# BL808 register map
File version: 0.1
Registers are access not given, no defined reset value unless marked. A register's access mark holds for its fields unless they carry their own. Offsets are from the block's base; [hi:lo] are bit positions; {n}, {i} and the like mark numbered series.

## GLB
Base 0x20000000
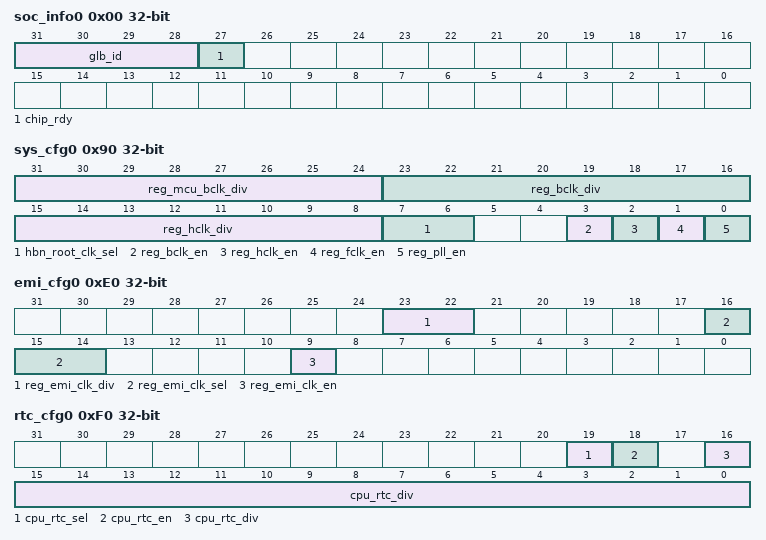
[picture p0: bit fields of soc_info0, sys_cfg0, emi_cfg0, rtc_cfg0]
0x00 soc_info0
  [31:28] glb_id ro, [27] chip_rdy ro
0x50 core_cfg16 ro
  [31:0] np_int_sta0
0x54 core_cfg17 ro
  [31:0] np_int_sta1
0x58 core_cfg18 rw
  [31:0] np_int_mask0
0x5C core_cfg19 rw
  [31:0] np_int_mask1
0x60 core_cfg20 write-once
  [31:0] np_int_clr0
0x64 core_cfg21 write-once
  [31:0] np_int_clr1
0x90 sys_cfg0
  [31:24] reg_mcu_bclk_div rw, [23:16] reg_bclk_div rw, [15:8] reg_hclk_div rw, [7:6] hbn_root_clk_sel ro, [3] reg_bclk_en rw, [2] reg_hclk_en rw, [1] reg_fclk_en rw, [0] reg_pll_en rw
0x94 sys_cfg1
  [26:24] fclk_sw_state ro
0xA0 bus_cfg0
  [15:0] rg_apb2_pck_force rw
0xE0 emi_cfg0
  [23:22] reg_emi_clk_div rw, [16:14] reg_emi_clk_sel rw, [9] reg_emi_clk_en rw
0xF0 rtc_cfg0
  [19] cpu_rtc_sel rw, [18] cpu_rtc_en rw, [16:0] cpu_rtc_div rw
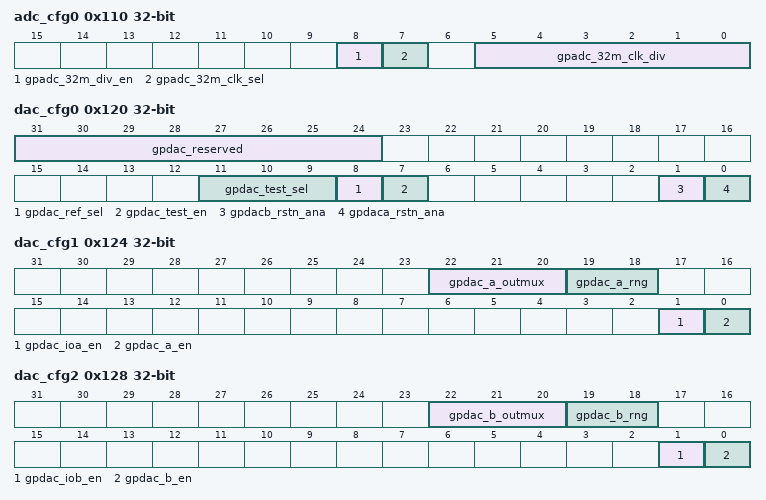
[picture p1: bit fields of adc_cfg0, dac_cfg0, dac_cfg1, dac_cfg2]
0x110 adc_cfg0
  [8] gpadc_32m_div_en rw, [7] gpadc_32m_clk_sel rw, [5:0] gpadc_32m_clk_div rw
0x120 dac_cfg0
  [31:24] gpdac_reserved rw, [11:9] gpdac_test_sel rw, [8] gpdac_ref_sel rw, [7] gpdac_test_en rw, [1] gpdacb_rstn_ana rw, [0] gpdaca_rstn_ana rw
0x124 dac_cfg1
  [22:20] gpdac_a_outmux rw, [19:18] gpdac_a_rng rw, [1] gpdac_ioa_en rw, [0] gpdac_a_en rw
0x128 dac_cfg2
  [22:20] gpdac_b_outmux rw, [19:18] gpdac_b_rng rw, [1] gpdac_iob_en rw, [0] gpdac_b_en rw
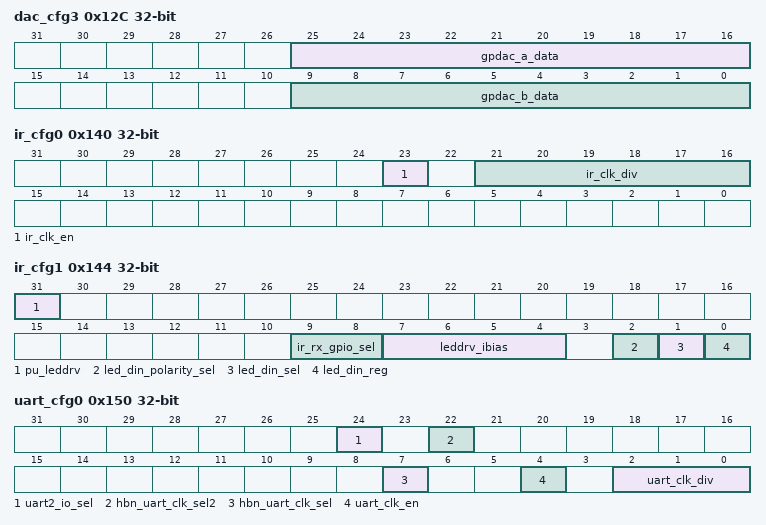
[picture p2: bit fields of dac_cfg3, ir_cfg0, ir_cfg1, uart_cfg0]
0x12C dac_cfg3
  [25:16] gpdac_a_data rw, [9:0] gpdac_b_data rw
0x130 dma_cfg0
  [31:24] dma_clk_en rw
0x134 dma_cfg1
  [31:24] dma2_clk_en rw
0x138 dma_cfg2 rw
  [31:0] reg_dma_cn_sel
0x140 ir_cfg0
  [23] ir_clk_en rw, [21:16] ir_clk_div rw
0x144 ir_cfg1
  [31] pu_leddrv rw, [9:8] ir_rx_gpio_sel rw, [7:4] leddrv_ibias rw, [2] led_din_polarity_sel rw, [1] led_din_sel rw, [0] led_din_reg rw
0x150 uart_cfg0
  [24] uart2_io_sel rw, [22] hbn_uart_clk_sel2 ro, [7] hbn_uart_clk_sel ro, [4] uart_clk_en rw, [2:0] uart_clk_div rw
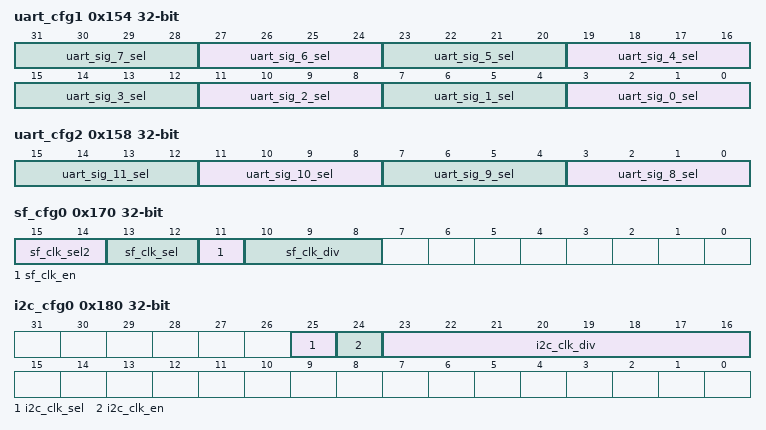
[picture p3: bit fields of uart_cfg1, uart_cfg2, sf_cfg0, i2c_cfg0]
0x154 uart_cfg1 rw
  [4n+3:4n] uart_sig_{n}_sel (n=0..7)
0x158 uart_cfg2
  [4n-29:4n-32] uart_sig_{n}_sel rw (n=8..11)
0x170 sf_cfg0
  [15:14] sf_clk_sel2 rw, [13:12] sf_clk_sel rw, [11] sf_clk_en rw, [10:8] sf_clk_div rw
0x180 i2c_cfg0
  [25] i2c_clk_sel rw, [24] i2c_clk_en rw, [23:16] i2c_clk_div rw
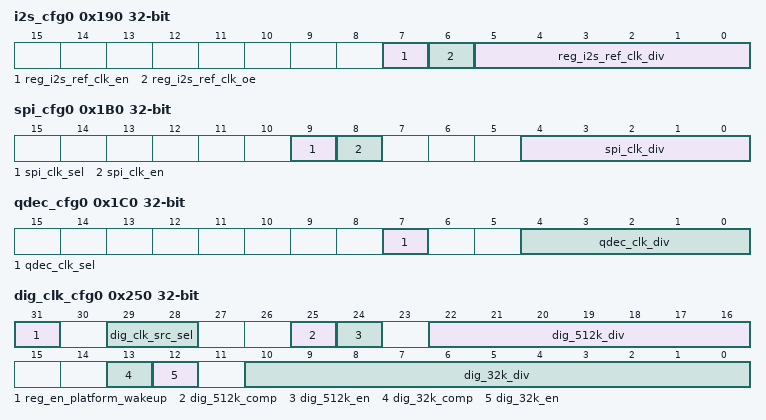
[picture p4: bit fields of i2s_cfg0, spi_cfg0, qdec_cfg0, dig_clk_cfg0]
0x190 i2s_cfg0
  [7] reg_i2s_ref_clk_en rw, [6] reg_i2s_ref_clk_oe rw, [5:0] reg_i2s_ref_clk_div rw
0x1B0 spi_cfg0
  [9] spi_clk_sel rw, [8] spi_clk_en rw, [4:0] spi_clk_div rw
0x1C0 qdec_cfg0
  [7] qdec_clk_sel rw, [4:0] qdec_clk_div rw
0x250 dig_clk_cfg0
  [31] reg_en_platform_wakeup rw, [29:28] dig_clk_src_sel rw, [25] dig_512k_comp rw, [24] dig_512k_en rw, [22:16] dig_512k_div rw, [13] dig_32k_comp rw, [12] dig_32k_en rw, [10:0] dig_32k_div rw
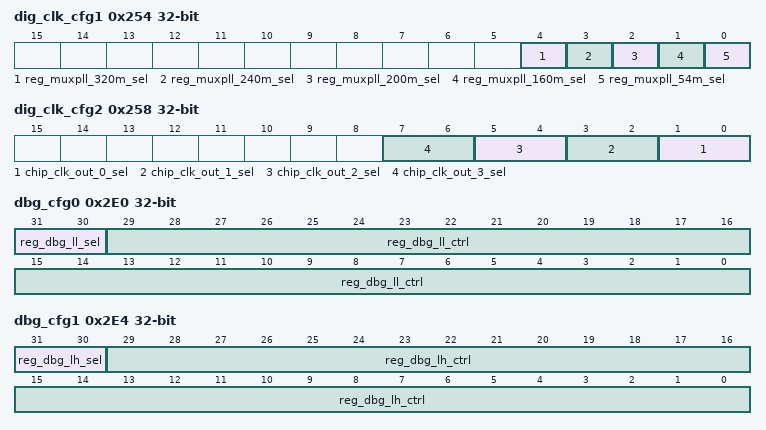
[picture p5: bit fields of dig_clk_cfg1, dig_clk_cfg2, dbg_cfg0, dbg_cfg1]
0x254 dig_clk_cfg1
  [4] reg_muxpll_320m_sel rw, [3] reg_muxpll_240m_sel rw, [2] reg_muxpll_200m_sel rw, [1] reg_muxpll_160m_sel rw, [0] reg_muxpll_54m_sel rw
0x258 dig_clk_cfg2
  [2n+1:2n] chip_clk_out_{n}_sel rw (n=0..3)
0x260 rf_cfg0
  [9] cfg_inv_rf2_test_clk_o rw
0x2E0 dbg_cfg0 rw
  [31:30] reg_dbg_ll_sel, [29:0] reg_dbg_ll_ctrl
0x2E4 dbg_cfg1 rw
  [31:30] reg_dbg_lh_sel, [29:0] reg_dbg_lh_ctrl
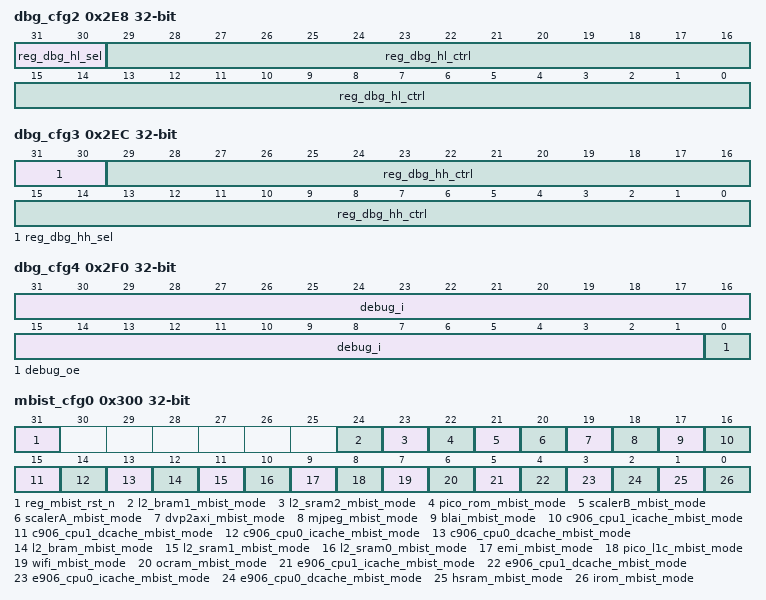
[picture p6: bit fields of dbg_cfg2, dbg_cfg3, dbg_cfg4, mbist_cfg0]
0x2E8 dbg_cfg2 rw
  [31:30] reg_dbg_hl_sel, [29:0] reg_dbg_hl_ctrl
0x2EC dbg_cfg3 rw
  [31:30] reg_dbg_hh_sel, [29:0] reg_dbg_hh_ctrl
0x2F0 dbg_cfg4 access per field
  [31:1] debug_i ro, [0] debug_oe rw
0x300 mbist_cfg0
  [31] reg_mbist_rst_n rw, [24] l2_bram1_mbist_mode rw, [23] l2_sram2_mbist_mode rw, [22] pico_rom_mbist_mode rw, [21] scalerB_mbist_mode rw, [20] scalerA_mbist_mode rw, [19] dvp2axi_mbist_mode rw, [18] mjpeg_mbist_mode rw, [17] blai_mbist_mode rw, [16] c906_cpu1_icache_mbist_mode rw, [15] c906_cpu1_dcache_mbist_mode rw, [14] c906_cpu0_icache_mbist_mode rw, [13] c906_cpu0_dcache_mbist_mode rw, [12] l2_bram_mbist_mode rw, [11] l2_sram1_mbist_mode rw, [10] l2_sram0_mbist_mode rw, [9] emi_mbist_mode rw, [8] pico_l1c_mbist_mode rw, [7] wifi_mbist_mode rw, [6] ocram_mbist_mode rw, [5] e906_cpu1_icache_mbist_mode rw, [4] e906_cpu1_dcache_mbist_mode rw, [3] e906_cpu0_icache_mbist_mode rw, [2] e906_cpu0_dcache_mbist_mode rw, [1] hsram_mbist_mode rw, [0] irom_mbist_mode rw
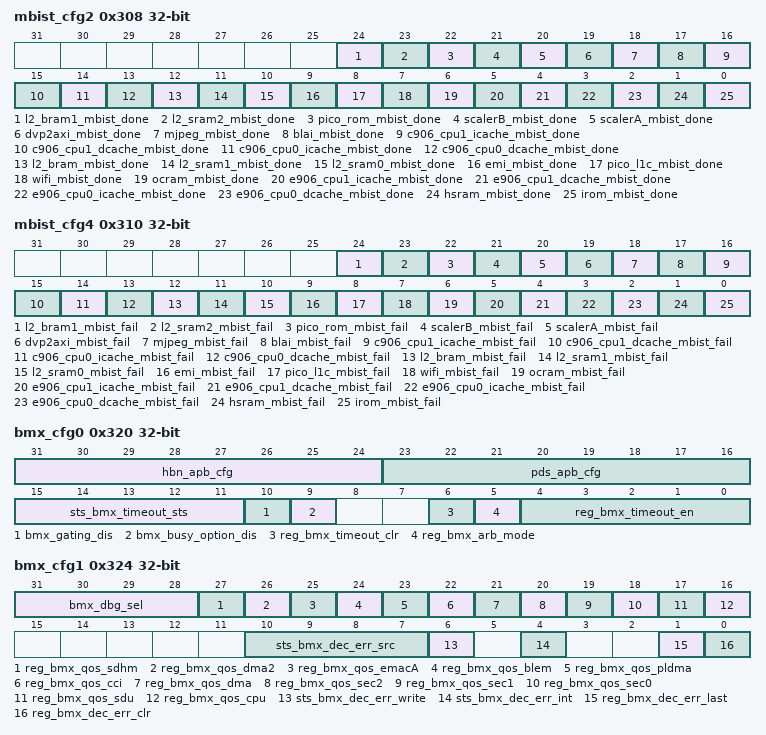
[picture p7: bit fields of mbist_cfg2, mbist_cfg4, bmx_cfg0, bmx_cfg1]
0x308 mbist_cfg2
  [24] l2_bram1_mbist_done ro, [23] l2_sram2_mbist_done ro, [22] pico_rom_mbist_done ro, [21] scalerB_mbist_done ro, [20] scalerA_mbist_done ro, [19] dvp2axi_mbist_done ro, [18] mjpeg_mbist_done ro, [17] blai_mbist_done ro, [16] c906_cpu1_icache_mbist_done ro, [15] c906_cpu1_dcache_mbist_done ro, [14] c906_cpu0_icache_mbist_done ro, [13] c906_cpu0_dcache_mbist_done ro, [12] l2_bram_mbist_done ro, [11] l2_sram1_mbist_done ro, [10] l2_sram0_mbist_done ro, [9] emi_mbist_done ro, [8] pico_l1c_mbist_done ro, [7] wifi_mbist_done ro, [6] ocram_mbist_done ro, [5] e906_cpu1_icache_mbist_done ro, [4] e906_cpu1_dcache_mbist_done ro, [3] e906_cpu0_icache_mbist_done ro, [2] e906_cpu0_dcache_mbist_done ro, [1] hsram_mbist_done ro, [0] irom_mbist_done ro
0x310 mbist_cfg4
  [24] l2_bram1_mbist_fail ro, [23] l2_sram2_mbist_fail ro, [22] pico_rom_mbist_fail ro, [21] scalerB_mbist_fail ro, [20] scalerA_mbist_fail ro, [19] dvp2axi_mbist_fail ro, [18] mjpeg_mbist_fail ro, [17] blai_mbist_fail ro, [16] c906_cpu1_icache_mbist_fail ro, [15] c906_cpu1_dcache_mbist_fail ro, [14] c906_cpu0_icache_mbist_fail ro, [13] c906_cpu0_dcache_mbist_fail ro, [12] l2_bram_mbist_fail ro, [11] l2_sram1_mbist_fail ro, [10] l2_sram0_mbist_fail ro, [9] emi_mbist_fail ro, [8] pico_l1c_mbist_fail ro, [7] wifi_mbist_fail ro, [6] ocram_mbist_fail ro, [5] e906_cpu1_icache_mbist_fail ro, [4] e906_cpu1_dcache_mbist_fail ro, [3] e906_cpu0_icache_mbist_fail ro, [2] e906_cpu0_dcache_mbist_fail ro, [1] hsram_mbist_fail ro, [0] irom_mbist_fail ro
0x320 bmx_cfg0
  [31:24] hbn_apb_cfg rw, [23:16] pds_apb_cfg rw, [15:11] sts_bmx_timeout_sts ro, [10] bmx_gating_dis rw, [9] bmx_busy_option_dis rw, [6] reg_bmx_timeout_clr rw, [5] reg_bmx_arb_mode rw, [4:0] reg_bmx_timeout_en rw
0x324 bmx_cfg1
  [31:28] bmx_dbg_sel rw, [27] reg_bmx_qos_sdhm rw, [26] reg_bmx_qos_dma2 rw, [25] reg_bmx_qos_emacA rw, [24] reg_bmx_qos_blem rw, [23] reg_bmx_qos_pldma rw, [22] reg_bmx_qos_cci rw, [21] reg_bmx_qos_dma rw, [20] reg_bmx_qos_sec2 rw, [19] reg_bmx_qos_sec1 rw, [18] reg_bmx_qos_sec0 rw, [17] reg_bmx_qos_sdu rw, [16] reg_bmx_qos_cpu rw, [10:7] sts_bmx_dec_err_src ro, [6] sts_bmx_dec_err_write ro, [4] sts_bmx_dec_err_int ro, [1] reg_bmx_dec_err_last rw, [0] reg_bmx_dec_err_clr rw
0x328 bmx_cfg2 ro
  [31:0] sts_bmx_dec_err_addr
0x32C bmx_cfg3 ro
  [31:0] bmx_dbg_out
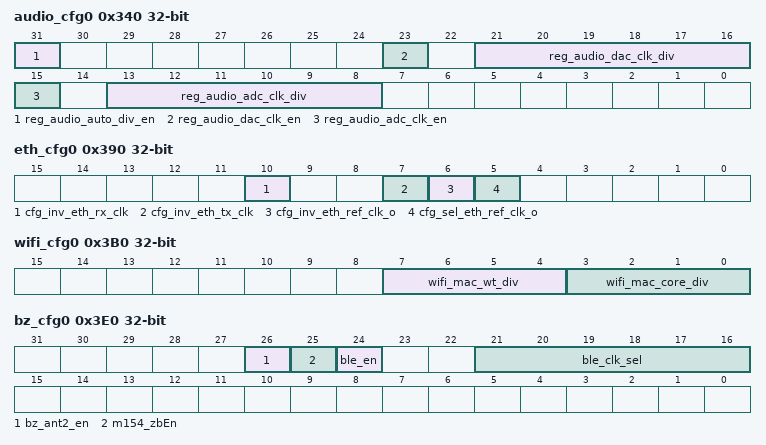
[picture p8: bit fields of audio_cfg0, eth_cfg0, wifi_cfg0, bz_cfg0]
0x340 audio_cfg0
  [31] reg_audio_auto_div_en rw, [23] reg_audio_dac_clk_en rw, [21:16] reg_audio_dac_clk_div rw, [15] reg_audio_adc_clk_en rw, [13:8] reg_audio_adc_clk_div rw
0x390 eth_cfg0
  [10] cfg_inv_eth_rx_clk rw, [7] cfg_inv_eth_tx_clk rw, [6] cfg_inv_eth_ref_clk_o rw, [5] cfg_sel_eth_ref_clk_o rw
0x3B0 wifi_cfg0
  [7:4] wifi_mac_wt_div rw, [3:0] wifi_mac_core_div rw
0x3D0 m154_cfg0
  [25] m1542_zbEn rw
0x3E0 bz_cfg0
  [26] bz_ant2_en rw, [25] m154_zbEn rw, [24] ble_en rw, [21:16] ble_clk_sel rw
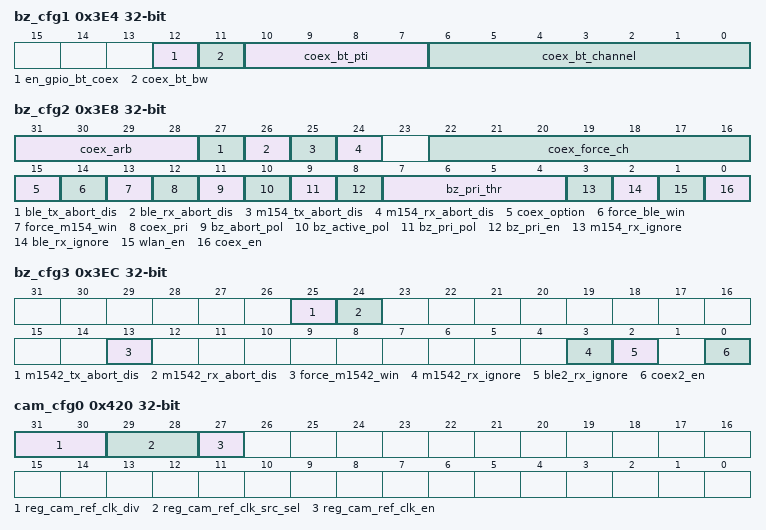
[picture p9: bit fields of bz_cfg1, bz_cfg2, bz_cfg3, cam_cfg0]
0x3E4 bz_cfg1
  [12] en_gpio_bt_coex rw, [11] coex_bt_bw rw, [10:7] coex_bt_pti rw, [6:0] coex_bt_channel rw
0x3E8 bz_cfg2
  [31:28] coex_arb ro, [27] ble_tx_abort_dis rw, [26] ble_rx_abort_dis rw, [25] m154_tx_abort_dis rw, [24] m154_rx_abort_dis rw, [22:16] coex_force_ch rw, [15] coex_option rw, [14] force_ble_win rw, [13] force_m154_win rw, [12] coex_pri rw, [11] bz_abort_pol rw, [10] bz_active_pol rw, [9] bz_pri_pol rw, [8] bz_pri_en rw, [7:4] bz_pri_thr rw, [3] m154_rx_ignore rw, [2] ble_rx_ignore rw, [1] wlan_en rw, [0] coex_en rw
0x3EC bz_cfg3
  [25] m1542_tx_abort_dis rw, [24] m1542_rx_abort_dis rw, [13] force_m1542_win rw, [3] m1542_rx_ignore rw, [2] ble2_rx_ignore rw, [0] coex2_en rw
0x420 cam_cfg0
  [31:30] reg_cam_ref_clk_div rw, [29:28] reg_cam_ref_clk_src_sel rw, [27] reg_cam_ref_clk_en rw
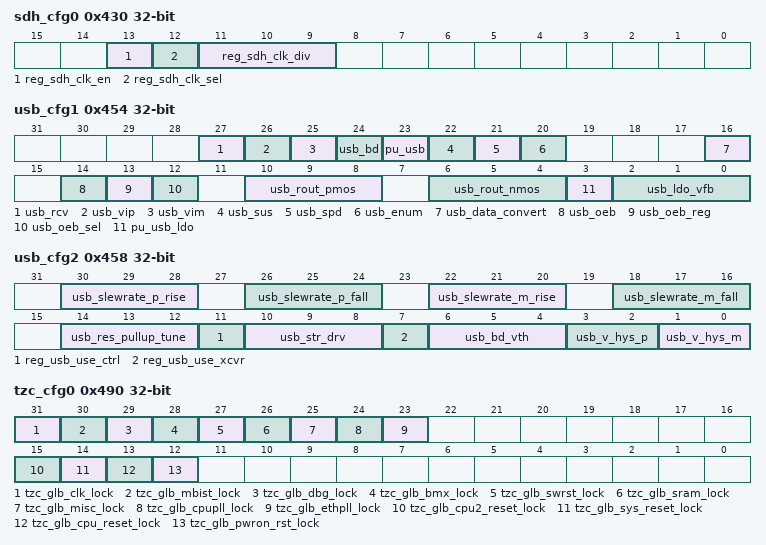
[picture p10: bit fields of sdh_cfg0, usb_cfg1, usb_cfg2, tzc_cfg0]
0x430 sdh_cfg0
  [13] reg_sdh_clk_en rw, [12] reg_sdh_clk_sel rw, [11:9] reg_sdh_clk_div rw
0x450 usb_cfg0
  [8] usb_clk_en rw
0x454 usb_cfg1
  [27] usb_rcv ro, [26] usb_vip ro, [25] usb_vim ro, [24] usb_bd ro, [23] pu_usb rw, [22] usb_sus rw, [21] usb_spd rw, [20] usb_enum rw, [16] usb_data_convert rw, [14] usb_oeb ro, [13] usb_oeb_reg rw, [12] usb_oeb_sel rw, [10:8] usb_rout_pmos rw, [6:4] usb_rout_nmos rw, [3] pu_usb_ldo rw, [2:0] usb_ldo_vfb rw
0x458 usb_cfg2
  [30:28] usb_slewrate_p_rise rw, [26:24] usb_slewrate_p_fall rw, [22:20] usb_slewrate_m_rise rw, [18:16] usb_slewrate_m_fall rw, [14:12] usb_res_pullup_tune rw, [11] reg_usb_use_ctrl rw, [10:8] usb_str_drv rw, [7] reg_usb_use_xcvr rw, [6:4] usb_bd_vth rw, [3:2] usb_v_hys_p rw, [1:0] usb_v_hys_m rw
0x490 tzc_cfg0
  [31] tzc_glb_clk_lock ro, [30] tzc_glb_mbist_lock ro, [29] tzc_glb_dbg_lock ro, [28] tzc_glb_bmx_lock ro, [27] tzc_glb_swrst_lock ro, [26] tzc_glb_sram_lock ro, [25] tzc_glb_misc_lock ro, [24] tzc_glb_cpupll_lock ro, [23] tzc_glb_ethpll_lock ro, [15] tzc_glb_cpu2_reset_lock ro, [14] tzc_glb_sys_reset_lock ro, [13] tzc_glb_cpu_reset_lock ro, [12] tzc_glb_pwron_rst_lock ro
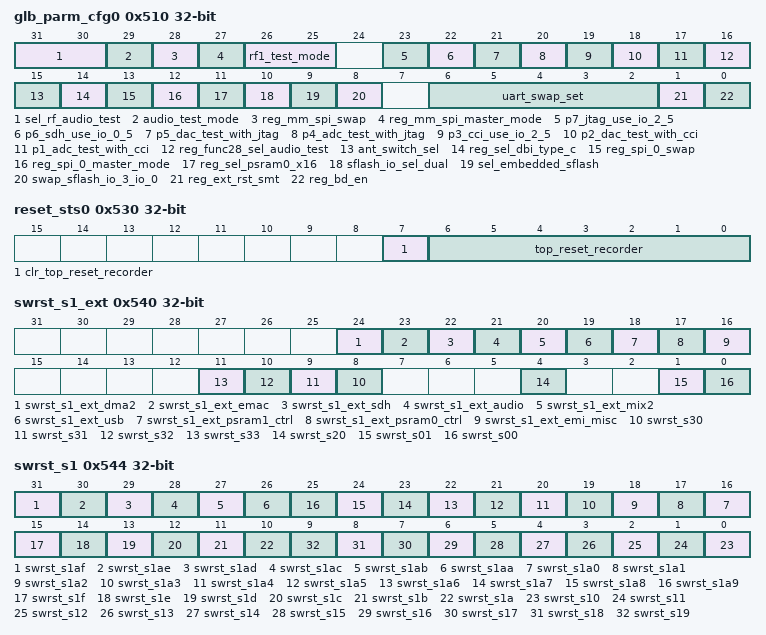
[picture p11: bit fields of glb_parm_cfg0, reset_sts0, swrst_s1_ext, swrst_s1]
0x510 glb_parm_cfg0
  [31:30] sel_rf_audio_test rw, [29] audio_test_mode rw, [28] reg_mm_spi_swap rw, [27] reg_mm_spi_master_mode rw, [26:25] rf1_test_mode rw, [23] p7_jtag_use_io_2_5 rw, [22] p6_sdh_use_io_0_5 rw, [21] p5_dac_test_with_jtag rw, [20] p4_adc_test_with_jtag rw, [19] p3_cci_use_io_2_5 rw, [18] p2_dac_test_with_cci rw, [17] p1_adc_test_with_cci rw, [16] reg_func28_sel_audio_test rw, [15] ant_switch_sel rw, [14] reg_sel_dbi_type_c rw, [13] reg_spi_0_swap rw, [12] reg_spi_0_master_mode rw, [11] reg_sel_psram0_x16 rw, [10] sflash_io_sel_dual rw, [9] sel_embedded_sflash rw, [8] swap_sflash_io_3_io_0 rw, [6:2] uart_swap_set rw, [1] reg_ext_rst_smt rw, [0] reg_bd_en rw
0x520 debug_cfg0
0x524 debug_cfg1
  [20] debug_ndreset_gate rw
0x530 reset_sts0
  [7] clr_top_reset_recorder rw, [6:0] top_reset_recorder ro
0x540 swrst_s1_ext + swrst_s3 + swrst_s2
  [24] swrst_s1_ext_dma2 rw, [23] swrst_s1_ext_emac rw, [22] swrst_s1_ext_sdh rw, [21] swrst_s1_ext_audio rw, [20] swrst_s1_ext_mix2 rw, [19] swrst_s1_ext_usb rw, [18] swrst_s1_ext_psram1_ctrl rw, [17] swrst_s1_ext_psram0_ctrl rw, [16] swrst_s1_ext_emi_misc rw, [n-22] swrst_s{n} rw (n=30..33), [4] swrst_s20 rw, [1] swrst_s01 rw, [0] swrst_s00 rw
0x544 swrst_s1 rw
  [31] swrst_s1af, [30] swrst_s1ae, [29] swrst_s1ad, [28] swrst_s1ac, [27] swrst_s1ab, [26] swrst_s1aa, [n+16] swrst_s1a{n} (n=0..9), [15] swrst_s1f, [14] swrst_s1e, [13] swrst_s1d, [12] swrst_s1c, [11] swrst_s1b, [10] swrst_s1a, [n-10] swrst_s{n} (n=10..19)
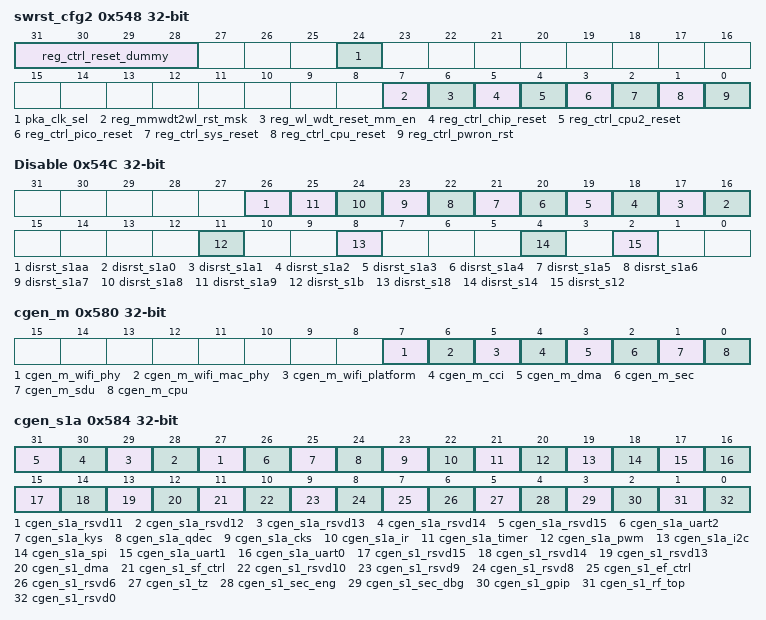
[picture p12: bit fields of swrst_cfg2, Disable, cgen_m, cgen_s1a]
0x548 swrst_cfg2
  [31:28] reg_ctrl_reset_dummy rw, [24] pka_clk_sel rw, [7] reg_mmwdt2wl_rst_msk rw, [6] reg_wl_wdt_reset_mm_en rw, [5] reg_ctrl_chip_reset rw, [4] reg_ctrl_cpu2_reset rw, [3] reg_ctrl_pico_reset rw, [2] reg_ctrl_sys_reset rw, [1] reg_ctrl_cpu_reset rw, [0] reg_ctrl_pwron_rst rw
0x54C Disable hreset
  [26] disrst_s1aa rw, [n+16] disrst_s1a{n} rw (n=0..9), [11] disrst_s1b rw, [8] disrst_s18 rw, [4] disrst_s14 rw, [2] disrst_s12 rw
0x580 cgen_m
  [7] cgen_m_wifi_phy rw, [6] cgen_m_wifi_mac_phy rw, [5] cgen_m_wifi_platform rw, [4] cgen_m_cci rw, [3] cgen_m_dma rw, [2] cgen_m_sec rw, [1] cgen_m_sdu rw, [0] cgen_m_cpu rw
0x584 cgen_s1a + cgen_s1 rw
  [n+16] cgen_s1a_rsvd{n} (n=11..15), [26] cgen_s1a_uart2, [25] cgen_s1a_kys, [24] cgen_s1a_qdec, [23] cgen_s1a_cks, [22] cgen_s1a_ir, [21] cgen_s1a_timer, [20] cgen_s1a_pwm, [19] cgen_s1a_i2c, [18] cgen_s1a_spi, [17] cgen_s1a_uart1, [16] cgen_s1a_uart0, [15] cgen_s1_rsvd15, [14] cgen_s1_rsvd14, [13] cgen_s1_rsvd13, [12] cgen_s1_dma, [11] cgen_s1_sf_ctrl, [10] cgen_s1_rsvd10, [9] cgen_s1_rsvd9, [8] cgen_s1_rsvd8, [7] cgen_s1_ef_ctrl, [6] cgen_s1_rsvd6, [5] cgen_s1_tz, [4] cgen_s1_sec_eng, [3] cgen_s1_sec_dbg, [2] cgen_s1_gpip, [1] cgen_s1_rf_top, [0] cgen_s1_rsvd0
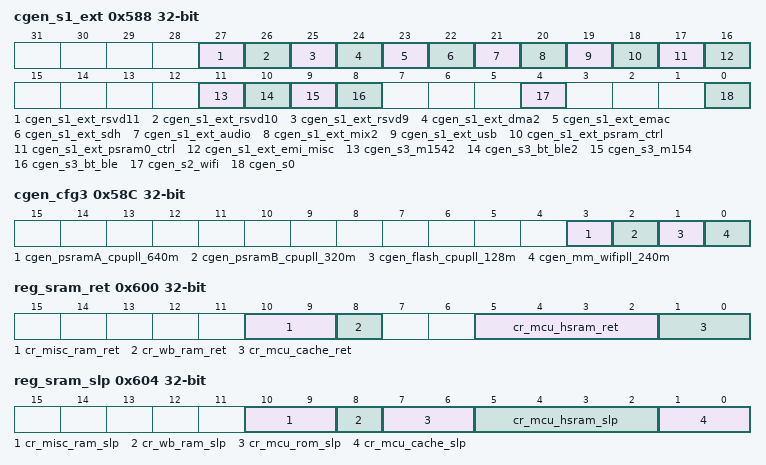
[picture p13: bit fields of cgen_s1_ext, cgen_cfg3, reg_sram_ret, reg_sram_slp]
0x588 cgen_s1_ext + cgen_s3
  [27] cgen_s1_ext_rsvd11 rw, [26] cgen_s1_ext_rsvd10 rw, [25] cgen_s1_ext_rsvd9 rw, [24] cgen_s1_ext_dma2 rw, [23] cgen_s1_ext_emac rw, [22] cgen_s1_ext_sdh rw, [21] cgen_s1_ext_audio rw, [20] cgen_s1_ext_mix2 rw, [19] cgen_s1_ext_usb rw, [18] cgen_s1_ext_psram_ctrl rw, [17] cgen_s1_ext_psram0_ctrl rw, [16] cgen_s1_ext_emi_misc rw, [11] cgen_s3_m1542 rw, [10] cgen_s3_bt_ble2 rw, [9] cgen_s3_m154 rw, [8] cgen_s3_bt_ble rw, [4] cgen_s2_wifi rw, [0] cgen_s0 rw
0x58C cgen_cfg3
  [3] cgen_psramA_cpupll_640m rw, [2] cgen_psramB_cpupll_320m rw, [1] cgen_flash_cpupll_128m rw, [0] cgen_mm_wifipll_240m rw
{0x5C0+4i} hw_rsv{i} (i=0..3)
0x600 reg_sram_ret
  [10:9] cr_misc_ram_ret rw, [8] cr_wb_ram_ret rw, [5:2] cr_mcu_hsram_ret rw, [1:0] cr_mcu_cache_ret rw
0x604 reg_sram_slp
  [10:9] cr_misc_ram_slp rw, [8] cr_wb_ram_slp rw, [7:6] cr_mcu_rom_slp rw, [5:2] cr_mcu_hsram_slp rw, [1:0] cr_mcu_cache_slp rw
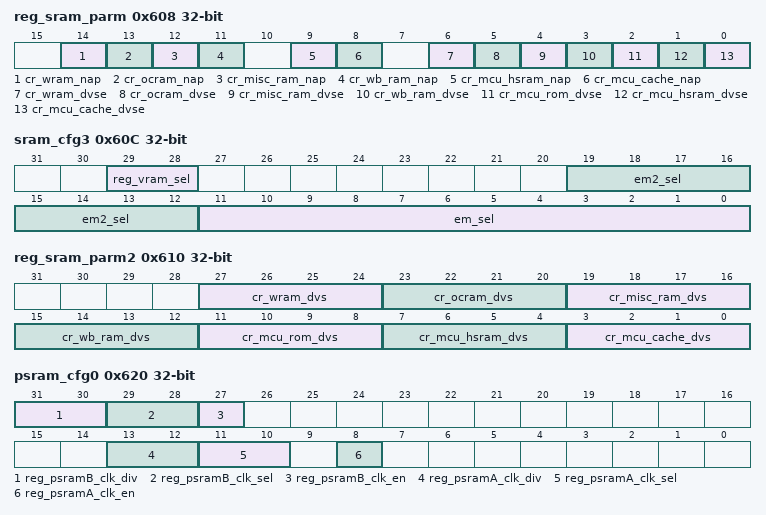
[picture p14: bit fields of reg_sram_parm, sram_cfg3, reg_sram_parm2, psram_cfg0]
0x608 reg_sram_parm
  [14] cr_wram_nap rw, [13] cr_ocram_nap rw, [12] cr_misc_ram_nap rw, [11] cr_wb_ram_nap rw, [9] cr_mcu_hsram_nap rw, [8] cr_mcu_cache_nap rw, [6] cr_wram_dvse rw, [5] cr_ocram_dvse rw, [4] cr_misc_ram_dvse rw, [3] cr_wb_ram_dvse rw, [2] cr_mcu_rom_dvse rw, [1] cr_mcu_hsram_dvse rw, [0] cr_mcu_cache_dvse rw
0x60C sram_cfg3
  [29:28] reg_vram_sel rw, [19:12] em2_sel rw, [11:0] em_sel rw
0x610 reg_sram_parm2
  [27:24] cr_wram_dvs rw, [23:20] cr_ocram_dvs rw, [19:16] cr_misc_ram_dvs rw, [15:12] cr_wb_ram_dvs rw, [11:8] cr_mcu_rom_dvs rw, [7:4] cr_mcu_hsram_dvs rw, [3:0] cr_mcu_cache_dvs rw
0x620 psram_cfg0
  [31:30] reg_psramB_clk_div rw, [29:28] reg_psramB_clk_sel rw, [27] reg_psramB_clk_en rw, [13:12] reg_psramA_clk_div rw, [11:10] reg_psramA_clk_sel rw, [8] reg_psramA_clk_en rw
0x6C0 pwr_cfg0
  [31:28] ldo18io_vout_trim rw, [27:24] ldo18io_vout_sel rw, [23] ldo18io_sstart rw, [22:20] ldo18io_sstart_delay rw, [17] ldo18io_pulldown_sel rw, [16] ldo18io_pulldown rw, [15] ldo18io_ocp rw, [14:12] ldo18io_ocp_th rw, [10:8] ldo18io_cc rw, [6:4] ldo18io_bm rw, [3] ldo18io_ocp_out ro, [2] ten_ldo18io rw, [1] ldo18io_bypass rw, [0] pu_ldo18io rw
0x700 dll_cfg0
  [31] ppu_dll rw, [30] pu_dll rw, [29] dll_reset rw, [28] dll_refclk_sel rw, [23] dll_cp_hiz rw, [22] dll_cp_op_en rw, [21:20] dll_delay_sel rw, [19:16] dll_post_div rw, [15] dll_vctrl_force_en rw, [14] dll_prechg_en rw, [13] dll_prechg_reg rw, [12] dll_prechg_sel rw, [10:8] dll_vctrl_sel rw, [7] dll_clk_57p6M_en rw, [6] dll_clk_96M_en rw, [5] dll_clk_144M_en rw, [4] dll_clk_288M_en rw, [3] dll_clk_mmdiv_en rw, [2] ten_dll rw, [1] dtest_en_dll_outclk rw, [0] dtest_en_dll_refclk rw
0x750 audio_pll_cfg0
  [10] pu_aupll rw, [9] pu_aupll_sfreg rw, [8] aupll_pu_cp rw, [7] aupll_pu_pfd rw, [6] aupll_pu_clamp_op rw, [5] aupll_pu_fbdv rw, [4] aupll_pu_postdiv rw, [3] aupll_reset_refdiv rw, [2] aupll_reset_fbdv rw, [1] aupll_reset_postdiv rw, [0] aupll_sdm_reset rw
0x754 audio_pll_cfg1
  [25:24] aupll_vg13_sel rw, [21:20] aupll_vg11_sel rw, [17:16] aupll_refclk_sel rw, [11:8] aupll_refdiv_ratio rw, [6:0] aupll_postdiv rw
0x758 audio_pll_cfg2
  [10] aupll_cp_opamp_en rw, [9] aupll_cp_startup_en rw, [8] aupll_int_frac_sw rw, [7:6] aupll_icp_1u rw, [5:4] aupll_icp_5u rw, [0] aupll_sel_cp_bias rw
0x75C audio_pll_cfg3
  [18:16] aupll_rz rw, [15:14] aupll_cz rw, [13:12] aupll_c3 rw, [8] aupll_r4_short rw, [5:4] aupll_r4 rw, [0] aupll_c4_en rw
0x760 audio_pll_cfg4
  [8] aupll_sdmclk_sel rw, [5:4] aupll_sel_fb_clk rw, [1:0] aupll_sel_sample_clk rw
0x764 audio_pll_cfg5
  [2:0] aupll_vco_speed rw
0x768 audio_pll_cfg6
  [24] aupll_sdm_bypass rw, [23:0] aupll_sdmin rw
0x76C audio_pll_cfg7
  [17:16] aupll_sdm_sig_dith_sel rw, [13:12] aupll_sdm_sig_prbs_sel rw, [8] aupll_sdm_noi_prbs_en rw, [5:4] aupll_sdm_noi_prbs_sel rw, [0] aupll_sdm_order_sel rw
0x770 audio_pll_cfg8
  [9] aupll_sel_div1_div2 rw, [8] aupll_en_div15 rw, [7] aupll_en_div10 rw, [n] aupll_en_div{n} rw (n=3..6), [2] aupll_en_div2p5 rw, [1] aupll_en_div2 rw, [0] aupll_en_div1 rw
0x774 audio_pll_cfg9
  [9] dten_aupll_postdiv_clk rw, [8] dten_aupll_div5 rw, [7] dten_aupll_div15 rw, [6] dten_aupll_fsdm rw, [5] dten_aupll_fref rw, [4] dten_aupll_fin rw, [2] ten_aupll_sfreg rw, [1] ten_aupll rw, [0] aupll_dc_tp_out_en rw
0x810 wifi_pll_cfg0
  [10] pu_wifipll rw, [9] pu_wifipll_sfreg rw, [8] wifipll_pu_cp rw, [7] wifipll_pu_pfd rw, [6] wifipll_pu_clamp_op rw, [5] wifipll_pu_fbdv rw, [4] wifipll_pu_postdiv rw, [3] wifipll_reset_refdiv rw, [2] wifipll_reset_fbdv rw, [1] wifipll_reset_postdiv rw, [0] wifipll_sdm_reset rw
0x814 wifi_pll_cfg1
  [25:24] wifipll_vg13_sel rw, [21:20] wifipll_vg11_sel rw, [17:16] wifipll_refclk_sel rw, [11:8] wifipll_refdiv_ratio rw, [6:0] wifipll_postdiv rw
0x818 wifi_pll_cfg2
  [10] wifipll_cp_opamp_en rw, [9] wifipll_cp_startup_en rw, [8] wifipll_int_frac_sw rw, [7:6] wifipll_icp_1u rw, [5:4] wifipll_icp_5u rw, [0] wifipll_sel_cp_bias rw
0x81C wifi_pll_cfg3
  [18:16] wifipll_rz rw, [15:14] wifipll_cz rw, [13:12] wifipll_c3 rw, [8] wifipll_r4_short rw, [5:4] wifipll_r4 rw, [0] wifipll_c4_en rw
0x820 wifi_pll_cfg4
  [8] wifipll_sdmclk_sel rw, [5:4] wifipll_sel_fb_clk rw, [1:0] wifipll_sel_sample_clk rw
0x824 wifi_pll_cfg5
  [2:0] wifipll_vco_speed rw
0x828 wifi_pll_cfg6
  [31] wifipll_sdm_ctrl_hw rw, [24] wifipll_sdm_bypass rw, [23:0] wifipll_sdmin rw
0x82C wifi_pll_cfg7
  [17:16] wifipll_sdm_sig_dith_sel rw, [13:12] wifipll_sdm_sig_prbs_sel rw, [8] wifipll_sdm_noi_prbs_en rw, [5:4] wifipll_sdm_noi_prbs_sel rw, [0] wifipll_sdm_order_sel rw
0x830 wifi_pll_cfg8
  [31] wifipll_en_ctrl_hw rw, [10] en_wifipll_div15_bz_adc rw, [9] wifipll_sel_div1_div2 rw, [8] wifipll_en_div15 rw, [7] wifipll_en_div10 rw, [n] wifipll_en_div{n} rw (n=3..6), [2] wifipll_en_div2p5 rw, [1] wifipll_en_div2 rw, [0] wifipll_en_div1 rw
0x834 wifi_pll_cfg9
  [9] dten_wifipll_postdiv_clk rw, [8] dten_wifipll_div5 rw, [7] dten_wifipll_div15 rw, [6] dten_wifipll_fsdm rw, [5] dten_wifipll_fref rw, [4] dten_wifipll_fin rw, [2] ten_wifipll_sfreg rw, [1] ten_wifipll rw, [0] wifipll_dc_tp_out_en rw
{0x8C4+4i} gpio_cfg{i} (i=0..50)
  [31:30] reg_gpio_{i}_mode rw, [28] reg_gpio_{i}_i ro, [26] reg_gpio_{i}_clr write-once, [25] reg_gpio_{i}_set write-once, [24] reg_gpio_{i}_o rw, [22] reg_gpio_{i}_int_mask rw, [21] gpio_{i}_int_stat ro, [20] reg_gpio_{i}_int_clr rw, [19:16] reg_gpio_{i}_int_mode_set rw, [12:8] reg_gpio_{i}_func_sel rw, [6] reg_gpio_{i}_oe rw, [5] reg_gpio_{i}_pd rw, [4] reg_gpio_{i}_pu rw, [3:2] reg_gpio_{i}_drv rw, [1] reg_gpio_{i}_smt rw, [0] reg_gpio_{i}_ie rw
{0x8C4+4i} gpio_cfg{i} (i=51..90)
  [5] reg_gpio_{i}_pd rw, [4] reg_gpio_{i}_pu rw, [3:2] reg_gpio_{i}_drv rw, [1] reg_gpio_{i}_smt rw, [0] reg_gpio_{i}_ie rw
{0x8C4+4i} gpio_cfg{i} (i=94..99)
0xAC4 gpio_cfg128 ro
  [n] reg2_gpio_{n}_i (n=0..31)
0xAC8 gpio_cfg129
  [n-32] reg2_gpio_{n}_i ro (n=32..50)
0xAE4 gpio_cfg136 rw
  [n] reg2_gpio_{n}_o (n=0..31)
0xAE8 gpio_cfg137
  [n-32] reg2_gpio_{n}_o rw (n=32..50)
0xAEC gpio_cfg138 write-once
  [n] reg2_gpio_{n}_set (n=0..31)
0xAF0 gpio_cfg139
  [n-32] reg2_gpio_{n}_set write-once (n=32..50)
0xAF8 gpio_cfg141
  [n-32] reg2_gpio_{n}_clr write-once (n=32..50)
0xAFC gpio_cfg142
  [31:24] cr_code1_high_time rw, [23:16] cr_code0_high_time rw, [15:7] cr_code_total_time rw, [2] cr_invert_code1_high rw, [1] cr_invert_code0_high rw, [0] cr_gpio_tx_en rw
0xB00 gpio_cfg143
  [31] cr_gpio_tx_fer_en rw, [30] cr_gpio_tx_fifo_en rw, [29] cr_gpio_tx_end_en rw, [28] r_gpio_tx_fer_int ro, [27] r_gpio_tx_fifo_int ro, [26] r_gpio_tx_end_int ro, [25] cr_gpio_tx_fer_mask rw, [24] cr_gpio_tx_fifo_mask rw, [23] cr_gpio_tx_end_mask rw, [22:16] cr_gpio_tx_fifo_th rw, [15:8] gpio_tx_fifo_cnt ro, [7] cr_gpio_dma_park_value rw, [5] gpio_tx_fifo_underflow ro, [4] gpio_tx_fifo_overflow ro, [3] gpio_tx_end_clr write-once, [2] gpio_tx_fifo_clr write-once, [1] cr_gpio_dma_out_sel_latch rw, [0] cr_gpio_dma_tx_en rw
0xB04 gpio_cfg144
  [15:0] gpio_tx_data_to_fifo wo
